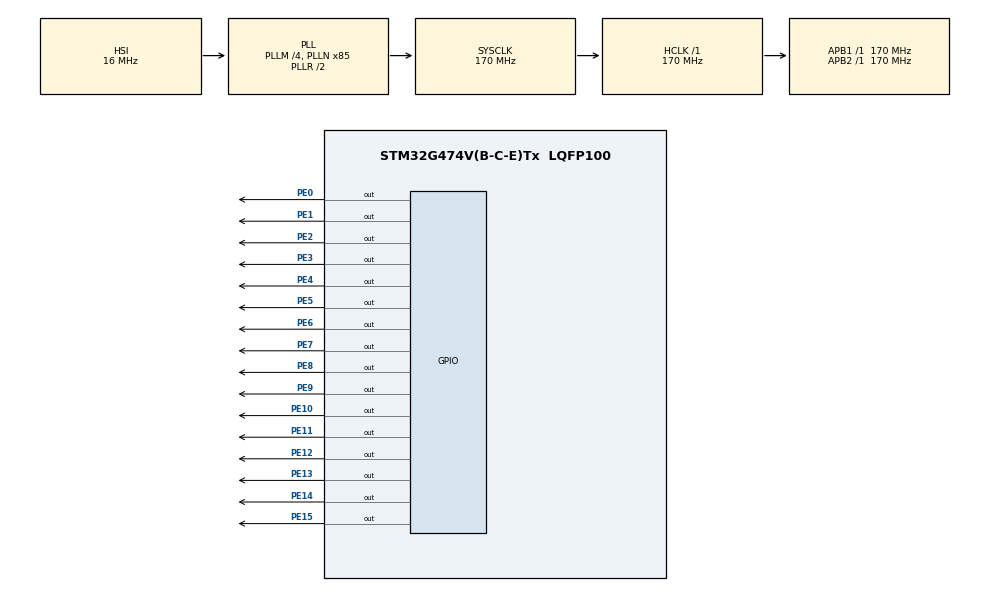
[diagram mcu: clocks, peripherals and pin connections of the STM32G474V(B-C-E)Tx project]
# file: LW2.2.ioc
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FREERTOS.Tasks01=defaultTask,0,128,StartDefaultTask,Default,NULL,Dynamic,NULL,NULL;myTask02,0,128,StartTask02,Default,NULL,Dynamic,NULL,NULL
Mcu.Family=STM32G4
Mcu.Name=STM32G474V(B-C-E)Tx
Mcu.Package=LQFP100
NVIC.PriorityGroup=NVIC_PRIORITYGROUP_4
NVIC.TIM2_IRQn=true\:15\:0\:false\:false\:true\:false\:false\:true\:true
NVIC.TimeBase=TIM2_IRQn
NVIC.TimeBaseIP=TIM2
PE0.GPIO_Speed=GPIO_SPEED_FREQ_VERY_HIGH
PE0.Signal=GPIO_Output
PE1.GPIO_Speed=GPIO_SPEED_FREQ_VERY_HIGH
PE1.Signal=GPIO_Output
PE10.GPIO_Speed=GPIO_SPEED_FREQ_VERY_HIGH
PE10.Signal=GPIO_Output
PE11.GPIO_Speed=GPIO_SPEED_FREQ_VERY_HIGH
PE11.Signal=GPIO_Output
PE12.GPIO_Speed=GPIO_SPEED_FREQ_VERY_HIGH
PE12.Signal=GPIO_Output
PE13.GPIO_Speed=GPIO_SPEED_FREQ_VERY_HIGH
PE13.Signal=GPIO_Output
PE14.GPIO_Speed=GPIO_SPEED_FREQ_VERY_HIGH
PE14.Signal=GPIO_Output
PE15.GPIO_Speed=GPIO_SPEED_FREQ_VERY_HIGH
PE15.Signal=GPIO_Output
PE2.GPIO_Speed=GPIO_SPEED_FREQ_VERY_HIGH
PE2.Signal=GPIO_Output
PE3.GPIO_Speed=GPIO_SPEED_FREQ_VERY_HIGH
PE3.Signal=GPIO_Output
PE4.GPIO_Speed=GPIO_SPEED_FREQ_VERY_HIGH
PE4.Signal=GPIO_Output
PE5.GPIO_Speed=GPIO_SPEED_FREQ_VERY_HIGH
PE5.Signal=GPIO_Output
PE6.GPIO_Speed=GPIO_SPEED_FREQ_VERY_HIGH
PE6.Signal=GPIO_Output
PE7.GPIO_Speed=GPIO_SPEED_FREQ_VERY_HIGH
PE7.Signal=GPIO_Output
PE8.GPIO_Speed=GPIO_SPEED_FREQ_VERY_HIGH
PE8.Signal=GPIO_Output
PE9.GPIO_Speed=GPIO_SPEED_FREQ_VERY_HIGH
PE9.Signal=GPIO_Output
ProjectManager.HeapSize=0x200
ProjectManager.StackSize=0x400
ProjectManager.TargetToolchain=STM32CubeIDE
RCC.ADC12Freq_Value=170000000
RCC.ADC345Freq_Value=170000000
RCC.AHBFreq_Value=170000000
RCC.APB1Freq_Value=170000000
RCC.APB1TimFreq_Value=170000000
RCC.APB2Freq_Value=170000000
RCC.APB2TimFreq_Value=170000000
RCC.CortexFreq_Value=170000000
RCC.EXTERNAL_CLOCK_VALUE=12288000
RCC.HCLKFreq_Value=170000000
RCC.HSE_VALUE=8000000
RCC.HSI48_VALUE=48000000
RCC.HSI_VALUE=16000000
RCC.LSE_VALUE=32768
RCC.PLLM=RCC_PLLM_DIV4
RCC.PLLN=85
RCC.SYSCLKFreq_VALUE=170000000
RCC.SYSCLKSource=RCC_SYSCLKSOURCE_PLLCLK
RCC.USBFreq_Value=170000000
RCC.VCOOutputFreq_Value=340000000
VP_FREERTOS_VS_CMSIS_V1.Mode=CMSIS_V1
VP_SYS_VS_DBSignals.Mode=DisableDeadBatterySignals
VP_SYS_VS_tim2.Mode=TIM2
board=custom

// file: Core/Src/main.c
/* USER CODE BEGIN Header */
/**
  ******************************************************************************
  * @file           : main.c
  * @brief          : Main program body
  ******************************************************************************
  * @attention
  *
  * Copyright (c) 2024 STMicroelectronics.
  * All rights reserved.
  *
  * This software is licensed under terms that can be found in the LICENSE file
  * in the root directory of this software component.
  * If no LICENSE file comes with this software, it is provided AS-IS.
  *
  ******************************************************************************
  */
/* USER CODE END Header */
#include "main.h"
#include "cmsis_os.h"

osThreadId defaultTaskHandle;
osThreadId myTask02Handle;

void SystemClock_Config(void);
static void MX_GPIO_Init(void);
void StartDefaultTask(void const * argument);
void StartTask02(void const * argument);

int main(void)
{

  /* MCU Configuration--------------------------------------------------------*/

  /* Reset of all peripherals, Initializes the Flash interface and the Systick. */
  HAL_Init();

  /* Configure the system clock */
  SystemClock_Config();

  /* Initialize all configured peripherals */
  MX_GPIO_Init();

  /* Create the thread(s) */
  /* definition and creation of defaultTask */
  osThreadDef(defaultTask, StartDefaultTask, osPriorityNormal, 0, 128);
  defaultTaskHandle = osThreadCreate(osThread(defaultTask), NULL);

  /* definition and creation of myTask02 */
  osThreadDef(myTask02, StartTask02, osPriorityNormal, 0, 128);
  myTask02Handle = osThreadCreate(osThread(myTask02), NULL);

  /* Start scheduler */
  osKernelStart();

  /* We should never get here as control is now taken by the scheduler */
  /* Infinite loop */
  while (1)
  {

  }
}

void SystemClock_Config(void)
{
  RCC_OscInitTypeDef RCC_OscInitStruct = {0};
  RCC_ClkInitTypeDef RCC_ClkInitStruct = {0};

  /** Configure the main internal regulator output voltage
  */
  HAL_PWREx_ControlVoltageScaling(PWR_REGULATOR_VOLTAGE_SCALE1_BOOST);

  /** Initializes the RCC Oscillators according to the specified parameters
  * in the RCC_OscInitTypeDef structure.
  */
  RCC_OscInitStruct.OscillatorType = RCC_OSCILLATORTYPE_HSI;
  RCC_OscInitStruct.HSIState = RCC_HSI_ON;
  RCC_OscInitStruct.HSICalibrationValue = RCC_HSICALIBRATION_DEFAULT;
  RCC_OscInitStruct.PLL.PLLState = RCC_PLL_ON;
  RCC_OscInitStruct.PLL.PLLSource = RCC_PLLSOURCE_HSI;
  RCC_OscInitStruct.PLL.PLLM = RCC_PLLM_DIV4;
  RCC_OscInitStruct.PLL.PLLN = 85;
  RCC_OscInitStruct.PLL.PLLP = RCC_PLLP_DIV2;
  RCC_OscInitStruct.PLL.PLLQ = RCC_PLLQ_DIV2;
  RCC_OscInitStruct.PLL.PLLR = RCC_PLLR_DIV2;
  if (HAL_RCC_OscConfig(&RCC_OscInitStruct) != HAL_OK)
  {
    Error_Handler();
  }

  /** Initializes the CPU, AHB and APB buses clocks
  */
  RCC_ClkInitStruct.ClockType = RCC_CLOCKTYPE_HCLK|RCC_CLOCKTYPE_SYSCLK
                              |RCC_CLOCKTYPE_PCLK1|RCC_CLOCKTYPE_PCLK2;
  RCC_ClkInitStruct.SYSCLKSource = RCC_SYSCLKSOURCE_PLLCLK;
  RCC_ClkInitStruct.AHBCLKDivider = RCC_SYSCLK_DIV1;
  RCC_ClkInitStruct.APB1CLKDivider = RCC_HCLK_DIV1;
  RCC_ClkInitStruct.APB2CLKDivider = RCC_HCLK_DIV1;

  if (HAL_RCC_ClockConfig(&RCC_ClkInitStruct, FLASH_LATENCY_4) != HAL_OK)
  {
    Error_Handler();
  }
}

static void MX_GPIO_Init(void)
{
  GPIO_InitTypeDef GPIO_InitStruct = {0};

  /* GPIO Ports Clock Enable */
  __HAL_RCC_GPIOE_CLK_ENABLE();

  /*Configure GPIO pin Output Level */
  HAL_GPIO_WritePin(GPIOE, GPIO_PIN_2|GPIO_PIN_3|GPIO_PIN_4|GPIO_PIN_5
                          |GPIO_PIN_6|GPIO_PIN_7|GPIO_PIN_8|GPIO_PIN_9
                          |GPIO_PIN_10|GPIO_PIN_11|GPIO_PIN_12|GPIO_PIN_13
                          |GPIO_PIN_14|GPIO_PIN_15|GPIO_PIN_0|GPIO_PIN_1, GPIO_PIN_RESET);

  /*Configure GPIO pins : PE2 PE3 PE4 PE5
                           PE6 PE7 PE8 PE9
                           PE10 PE11 PE12 PE13
                           PE14 PE15 PE0 PE1 */
  GPIO_InitStruct.Pin = GPIO_PIN_2|GPIO_PIN_3|GPIO_PIN_4|GPIO_PIN_5
                          |GPIO_PIN_6|GPIO_PIN_7|GPIO_PIN_8|GPIO_PIN_9
                          |GPIO_PIN_10|GPIO_PIN_11|GPIO_PIN_12|GPIO_PIN_13
                          |GPIO_PIN_14|GPIO_PIN_15|GPIO_PIN_0|GPIO_PIN_1;
  GPIO_InitStruct.Mode = GPIO_MODE_OUTPUT_PP;
  GPIO_InitStruct.Pull = GPIO_NOPULL;
  GPIO_InitStruct.Speed = GPIO_SPEED_FREQ_VERY_HIGH;
  HAL_GPIO_Init(GPIOE, &GPIO_InitStruct);

}

void StartDefaultTask(void const * argument)
{
  /* USER CODE BEGIN 5 */
  /* Infinite loop */
  while(1)
  {
    for(int i = 0; i < 8; i++)
    {
			HAL_GPIO_WritePin(GPIOE, GPIO_PIN_0 << i, GPIO_PIN_SET);
			HAL_Delay(500);
			HAL_GPIO_WritePin(GPIOE, GPIO_PIN_0 << i, GPIO_PIN_RESET);
    }
  }
  /* USER CODE END 5 */
}

void StartTask02(void const * argument)
{
  /* USER CODE BEGIN StartTask02 */
  /* Infinite loop */
  while(1)
  {
    for(int i = 0; i < 8; i++)
    {
			HAL_GPIO_WritePin(GPIOE, GPIO_PIN_0 << i, GPIO_PIN_SET);
			HAL_Delay(250);
			HAL_GPIO_WritePin(GPIOE, GPIO_PIN_0 << i, GPIO_PIN_RESET);
		}
  }
  /* USER CODE END StartTask02 */
}

void HAL_TIM_PeriodElapsedCallback(TIM_HandleTypeDef *htim)
{
  if (htim->Instance == TIM2) {
    HAL_IncTick();
  }
}

void Error_Handler(void)
{
  __disable_irq();
  while (1)
  {
  }
}
